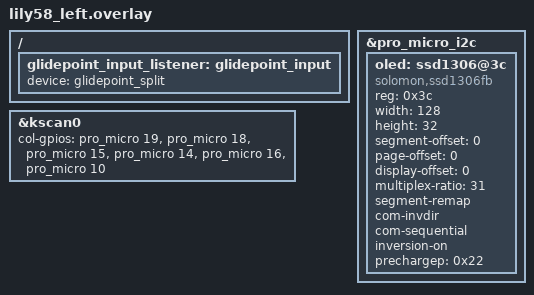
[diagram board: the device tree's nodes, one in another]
/*
 * Copyright (c) 2020 Pete Johanson
 *
 * SPDX-License-Identifier: MIT
 */

#include "lily58.dtsi"
#include "cirque.dtsi"


&kscan0 {
    col-gpios
        = <&pro_micro 19 GPIO_ACTIVE_HIGH>
        , <&pro_micro 18 GPIO_ACTIVE_HIGH>
        , <&pro_micro 15 GPIO_ACTIVE_HIGH>
        , <&pro_micro 14 GPIO_ACTIVE_HIGH>
        , <&pro_micro 16 GPIO_ACTIVE_HIGH>
        , <&pro_micro 10 GPIO_ACTIVE_HIGH>
        ;
};

// Cirque Trackpad ZMK Input Split
/ {
    glidepoint_input_listener: glidepoint_input {
        //compatible = "zmk,input-listener";    // Don't need this if there's one in .keymap
        device = <&glidepoint_split>;
    };
};

&pro_micro_i2c {
    // status = "disabled";
    status = "okay";

    oled: ssd1306@3c {
        compatible = "solomon,ssd1306fb";
        reg = <0x3c>;
        width = <128>;
        height = <32>;
        segment-offset = <0>;
        page-offset = <0>;
        display-offset = <0>;
        multiplex-ratio = <31>;
        segment-remap;
        com-invdir;
        com-sequential;
        inversion-on;
        prechargep = <0x22>;
    };
};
